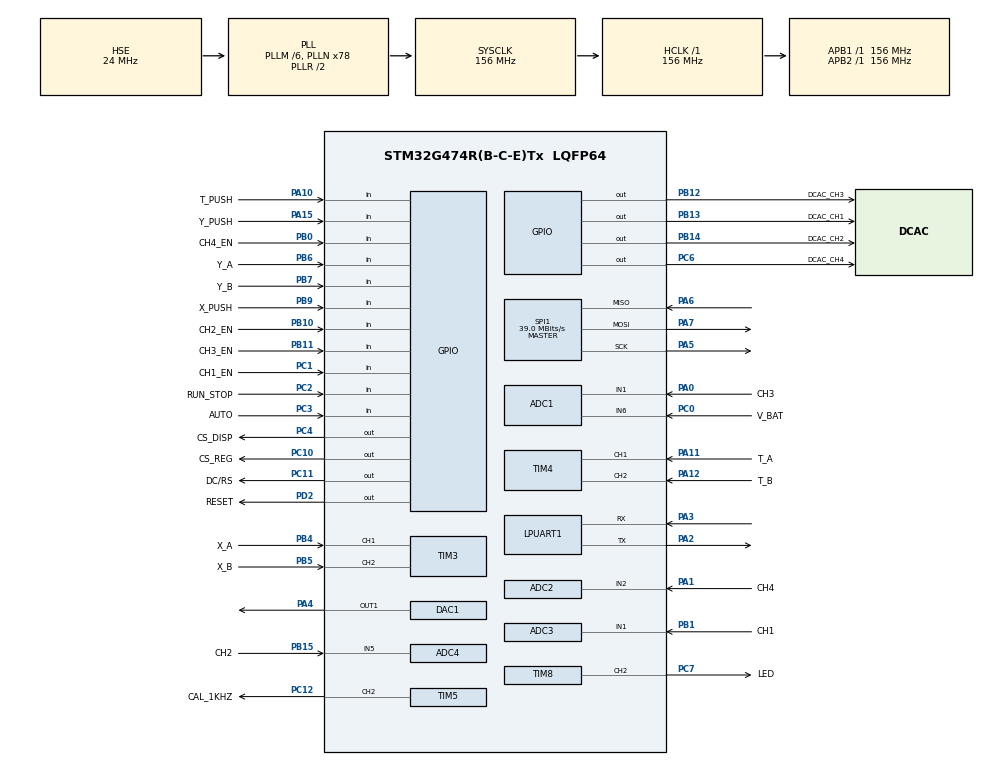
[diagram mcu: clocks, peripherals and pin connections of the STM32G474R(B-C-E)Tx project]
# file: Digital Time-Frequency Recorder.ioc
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ADC1.Channel-0\#ChannelRegularConversion=ADC_CHANNEL_1
ADC1.ClockPrescaler=ADC_CLOCK_ASYNC_DIV1
ADC1.DMAAccessModeView=ENABLE
ADC1.DMAContinuousRequests=ENABLE
ADC1.ExternalTrigConv=ADC_EXTERNALTRIG_T6_TRGO
ADC1.Mode=ADC_DUALMODE_REGSIMULT
ADC1.NbrOfConversion=1
ADC1.NbrOfConversionFlag=1
ADC1.OffsetNumber-0\#ChannelRegularConversion=ADC_OFFSET_NONE
ADC1.Overrun=ADC_OVR_DATA_OVERWRITTEN
ADC1.Rank-0\#ChannelRegularConversion=1
ADC1.SamplingTime-0\#ChannelRegularConversion=ADC_SAMPLETIME_2CYCLES_5
ADC1.master=1
ADC2.Channel-1\#ChannelRegularConversion=ADC_CHANNEL_2
ADC2.ClockPrescaler=ADC_CLOCK_ASYNC_DIV1
ADC2.DMAAccessModeView=ENABLE
ADC2.Mode=ADC_DUALMODE_REGSIMULT
ADC2.NbrOfConversionFlag=1
ADC2.OffsetNumber-1\#ChannelRegularConversion=ADC_OFFSET_NONE
ADC2.Rank-1\#ChannelRegularConversion=1
ADC2.SamplingTime-1\#ChannelRegularConversion=ADC_SAMPLETIME_2CYCLES_5
ADC3.Channel-3\#ChannelRegularConversion=ADC_CHANNEL_1
ADC3.ClockPrescaler=ADC_CLOCK_ASYNC_DIV1
ADC3.DMAAccessModeView=ENABLE
ADC3.DMAContinuousRequests=ENABLE
ADC3.ExternalTrigConv=ADC_EXTERNALTRIG_T6_TRGO
ADC3.Mode=ADC_DUALMODE_REGSIMULT
ADC3.NbrOfConversion=1
ADC3.NbrOfConversionFlag=1
ADC3.OffsetNumber-3\#ChannelRegularConversion=ADC_OFFSET_NONE
ADC3.Overrun=ADC_OVR_DATA_OVERWRITTEN
ADC3.Rank-3\#ChannelRegularConversion=1
ADC3.SamplingTime-3\#ChannelRegularConversion=ADC_SAMPLETIME_2CYCLES_5
ADC3.master=1
ADC4.Channel-1\#ChannelRegularConversion=ADC_CHANNEL_5
ADC4.ClockPrescaler=ADC_CLOCK_ASYNC_DIV1
ADC4.DMAAccessModeView=ENABLE
ADC4.Mode=ADC_DUALMODE_REGSIMULT
ADC4.NbrOfConversionFlag=1
ADC4.OffsetNumber-1\#ChannelRegularConversion=ADC_OFFSET_NONE
ADC4.Rank-1\#ChannelRegularConversion=1
ADC4.SamplingTime-1\#ChannelRegularConversion=ADC_SAMPLETIME_2CYCLES_5
DAC1.DAC_Trigger_OUT1-DAC_OUT1=DAC_TRIGGER_T2_TRGO
Dma.ADC1.2.Direction=DMA_PERIPH_TO_MEMORY
Dma.ADC1.2.EventEnable=DISABLE
Dma.ADC1.2.Instance=DMA1_Channel3
Dma.ADC1.2.MemDataAlignment=DMA_MDATAALIGN_WORD
Dma.ADC1.2.MemInc=DMA_MINC_ENABLE
Dma.ADC1.2.Mode=DMA_NORMAL
Dma.ADC1.2.PeriphDataAlignment=DMA_PDATAALIGN_WORD
Dma.ADC1.2.PeriphInc=DMA_PINC_DISABLE
Dma.ADC1.2.Polarity=HAL_DMAMUX_REQ_GEN_RISING
Dma.ADC1.2.Priority=DMA_PRIORITY_VERY_HIGH
Dma.ADC1.2.RequestNumber=1
Dma.ADC1.2.SignalID=NONE
Dma.ADC1.2.SyncEnable=DISABLE
Dma.ADC1.2.SyncPolarity=HAL_DMAMUX_SYNC_NO_EVENT
Dma.ADC1.2.SyncRequestNumber=1
Dma.ADC1.2.SyncSignalID=NONE
Dma.ADC3.3.Direction=DMA_PERIPH_TO_MEMORY
Dma.ADC3.3.EventEnable=DISABLE
Dma.ADC3.3.Instance=DMA1_Channel4
Dma.ADC3.3.MemDataAlignment=DMA_MDATAALIGN_WORD
Dma.ADC3.3.MemInc=DMA_MINC_ENABLE
Dma.ADC3.3.Mode=DMA_NORMAL
Dma.ADC3.3.PeriphDataAlignment=DMA_PDATAALIGN_WORD
Dma.ADC3.3.PeriphInc=DMA_PINC_DISABLE
Dma.ADC3.3.Polarity=HAL_DMAMUX_REQ_GEN_RISING
Dma.ADC3.3.Priority=DMA_PRIORITY_VERY_HIGH
Dma.ADC3.3.RequestNumber=1
Dma.ADC3.3.SignalID=NONE
Dma.ADC3.3.SyncEnable=DISABLE
Dma.ADC3.3.SyncPolarity=HAL_DMAMUX_SYNC_NO_EVENT
Dma.ADC3.3.SyncRequestNumber=1
Dma.ADC3.3.SyncSignalID=NONE
Dma.DAC1_CH1.1.Direction=DMA_MEMORY_TO_PERIPH
Dma.DAC1_CH1.1.EventEnable=DISABLE
Dma.DAC1_CH1.1.Instance=DMA1_Channel2
Dma.DAC1_CH1.1.MemDataAlignment=DMA_MDATAALIGN_HALFWORD
Dma.DAC1_CH1.1.MemInc=DMA_MINC_ENABLE
Dma.DAC1_CH1.1.Mode=DMA_CIRCULAR
Dma.DAC1_CH1.1.PeriphDataAlignment=DMA_PDATAALIGN_WORD
Dma.DAC1_CH1.1.PeriphInc=DMA_PINC_DISABLE
Dma.DAC1_CH1.1.Polarity=HAL_DMAMUX_REQ_GEN_RISING
Dma.DAC1_CH1.1.Priority=DMA_PRIORITY_LOW
Dma.DAC1_CH1.1.RequestNumber=1
Dma.DAC1_CH1.1.SignalID=NONE
Dma.DAC1_CH1.1.SyncEnable=DISABLE
Dma.DAC1_CH1.1.SyncPolarity=HAL_DMAMUX_SYNC_NO_EVENT
Dma.DAC1_CH1.1.SyncRequestNumber=1
Dma.DAC1_CH1.1.SyncSignalID=NONE
Dma.Request0=SPI1_TX
Dma.Request1=DAC1_CH1
Dma.Request2=ADC1
Dma.Request3=ADC3
Dma.SPI1_TX.0.Direction=DMA_MEMORY_TO_PERIPH
Dma.SPI1_TX.0.EventEnable=DISABLE
Dma.SPI1_TX.0.Instance=DMA1_Channel1
Dma.SPI1_TX.0.MemDataAlignment=DMA_MDATAALIGN_BYTE
Dma.SPI1_TX.0.MemInc=DMA_MINC_ENABLE
Dma.SPI1_TX.0.Mode=DMA_NORMAL
Dma.SPI1_TX.0.PeriphDataAlignment=DMA_PDATAALIGN_BYTE
Dma.SPI1_TX.0.PeriphInc=DMA_PINC_DISABLE
Dma.SPI1_TX.0.Polarity=HAL_DMAMUX_REQ_GEN_RISING
Dma.SPI1_TX.0.Priority=DMA_PRIORITY_HIGH
Dma.SPI1_TX.0.RequestNumber=1
Dma.SPI1_TX.0.SignalID=NONE
Dma.SPI1_TX.0.SyncEnable=DISABLE
Dma.SPI1_TX.0.SyncPolarity=HAL_DMAMUX_SYNC_NO_EVENT
Dma.SPI1_TX.0.SyncRequestNumber=1
Dma.SPI1_TX.0.SyncSignalID=NONE
Mcu.Family=STM32G4
Mcu.Name=STM32G474R(B-C-E)Tx
Mcu.Package=LQFP64
NVIC.DMA1_Channel1_IRQn=true\:0\:0\:false\:false\:true\:false\:true\:true
NVIC.DMA1_Channel2_IRQn=true\:0\:0\:false\:false\:true\:false\:true\:true
NVIC.DMA1_Channel3_IRQn=true\:0\:0\:false\:false\:true\:false\:true\:true
NVIC.DMA1_Channel4_IRQn=true\:0\:0\:false\:false\:true\:false\:true\:true
NVIC.PriorityGroup=NVIC_PRIORITYGROUP_4
NVIC.TIM7_DAC_IRQn=true\:0\:0\:false\:false\:true\:true\:true\:true
PA0.GPIO_Label=CH3
PA0.Mode=IN1-Single-Ended
PA0.Signal=ADC1_IN1
PA1.GPIO_Label=CH4
PA1.Mode=IN2-Single-Ended
PA1.Signal=ADC2_IN2
PA10.GPIO_Label=T_PUSH
PA10.Signal=GPIO_Input
PA11.GPIO_Label=T_A
PA11.Signal=S_TIM4_CH1
PA12.GPIO_Label=T_B
PA12.Signal=S_TIM4_CH2
PA13.GPIO_Label=T_SWDIO
PA13.Mode=Serial_Wire
PA13.Signal=SYS_JTMS-SWDIO
PA14.GPIO_Label=T_SWCLK
PA14.Mode=Serial_Wire
PA14.Signal=SYS_JTCK-SWCLK
PA15.GPIO_Label=Y_PUSH
PA15.Signal=GPIO_Input
PA2.Mode=Asynchronous
PA2.Signal=LPUART1_TX
PA3.Mode=Asynchronous
PA3.Signal=LPUART1_RX
PA4.Signal=COMP_DAC11_group
PA5.GPIO_Speed=GPIO_SPEED_FREQ_VERY_HIGH
PA5.Mode=Full_Duplex_Master
PA5.Signal=SPI1_SCK
PA6.GPIO_Speed=GPIO_SPEED_FREQ_VERY_HIGH
PA6.Mode=Full_Duplex_Master
PA6.Signal=SPI1_MISO
PA7.GPIO_Speed=GPIO_SPEED_FREQ_VERY_HIGH
PA7.Mode=Full_Duplex_Master
PA7.Signal=SPI1_MOSI
PB0.GPIO_Label=CH4_EN
PB0.Signal=GPIO_Input
PB1.GPIO_Label=CH1
PB1.Mode=IN1-Single-Ended
PB1.Signal=ADC3_IN1
PB10.GPIO_Label=CH2_EN
PB10.Signal=GPIO_Input
PB11.GPIO_Label=CH3_EN
PB11.Signal=GPIO_Input
PB12.GPIO_Label=DCAC_CH3
PB12.Signal=GPIO_Output
PB13.GPIO_Label=DCAC_CH1
PB13.Signal=GPIO_Output
PB14.GPIO_Label=DCAC_CH2
PB14.Signal=GPIO_Output
PB15.GPIO_Label=CH2
PB15.Mode=IN5-Single-Ended
PB15.Signal=ADC4_IN5
PB3.GPIO_Label=T_SWO
PB3.Signal=SYS_JTDO-SWO
PB4.GPIO_Label=X_A
PB4.Signal=S_TIM3_CH1
PB5.GPIO_Label=X_B
PB5.Signal=S_TIM3_CH2
PB6.GPIO_Label=Y_A
PB6.Signal=GPIO_Input
PB7.GPIO_Label=Y_B
PB7.Signal=GPIO_Input
PB9.GPIO_Label=X_PUSH
PB9.Signal=GPIO_Input
PC0.GPIO_Label=V_BAT
PC0.Mode=IN6-Single-Ended
PC0.Signal=ADC1_IN6
PC1.GPIO_Label=CH1_EN
PC1.Signal=GPIO_Input
PC10.GPIO_Label=CS_REG
PC10.PinState=GPIO_PIN_SET
PC10.Signal=GPIO_Output
PC11.GPIO_Label=DC/RS
PC11.Signal=GPIO_Output
PC12.GPIO_Label=CAL_1KHZ
PC12.Signal=S_TIM5_CH2
PC14-OSC32_IN.GPIO_Label=RCC_OSC32_IN
PC14-OSC32_IN.Signal=RCC_OSC32_IN
PC15-OSC32_OUT.GPIO_Label=RCC_OSC32_OUT
PC15-OSC32_OUT.Signal=RCC_OSC32_OUT
PC2.GPIO_Label=RUN_STOP
PC2.Signal=GPIO_Input
PC3.GPIO_Label=AUTO
PC3.Signal=GPIO_Input
PC4.GPIO_Label=CS_DISP
PC4.PinState=GPIO_PIN_SET
PC4.Signal=GPIO_Output
PC6.GPIO_Label=DCAC_CH4
PC6.Signal=GPIO_Output
PC7.GPIO_Label=LED
PC7.Signal=S_TIM8_CH2
PD2.GPIO_Label=RESET
PD2.PinState=GPIO_PIN_SET
PD2.Signal=GPIO_Output
PF0-OSC_IN.GPIO_Label=RCC_OSC_IN
PF0-OSC_IN.Mode=HSE-External-Oscillator
PF0-OSC_IN.Signal=RCC_OSC_IN
PF1-OSC_OUT.GPIO_Label=RCC_OSC_OUT
PF1-OSC_OUT.Mode=HSE-External-Oscillator
PF1-OSC_OUT.Signal=RCC_OSC_OUT
ProjectManager.HeapSize=0x1000
ProjectManager.StackSize=0x800
ProjectManager.TargetToolchain=STM32CubeIDE
RCC.ADC12CLockSelection=RCC_ADC12CLKSOURCE_PLL
RCC.ADC12Freq_Value=52000000
RCC.ADC345CLockSelection=RCC_ADC345CLKSOURCE_PLL
RCC.ADC345Freq_Value=52000000
RCC.AHBFreq_Value=156000000
RCC.APB1Freq_Value=156000000
RCC.APB1TimFreq_Value=156000000
RCC.APB2Freq_Value=156000000
RCC.APB2TimFreq_Value=156000000
RCC.CortexFreq_Value=156000000
RCC.EXTERNAL_CLOCK_VALUE=12288000
RCC.HCLKFreq_Value=156000000
RCC.HSE_VALUE=24000000
RCC.HSI48_VALUE=48000000
RCC.HSI_VALUE=16000000
RCC.LSE_VALUE=32768
RCC.PLLM=RCC_PLLM_DIV6
RCC.PLLN=78
RCC.PLLP=RCC_PLLP_DIV6
RCC.PLLSourceVirtual=RCC_PLLSOURCE_HSE
RCC.RTCClockSelection=RCC_RTCCLKSOURCE_LSE
RCC.SYSCLKFreq_VALUE=156000000
RCC.SYSCLKSource=RCC_SYSCLKSOURCE_PLLCLK
RCC.USBFreq_Value=156000000
RCC.VCOOutputFreq_Value=312000000
SH.COMP_DAC11_group.0=DAC1_OUT1,DAC_OUT1
SH.S_TIM3_CH1.0=TIM3_CH1,Encoder_Interface
SH.S_TIM3_CH2.0=TIM3_CH2,Encoder_Interface
SH.S_TIM4_CH1.0=TIM4_CH1,Encoder_Interface
SH.S_TIM4_CH2.0=TIM4_CH2,Encoder_Interface
SH.S_TIM5_CH2.0=TIM5_CH2,PWM Generation2 CH2
SH.S_TIM8_CH2.0=TIM8_CH2,PWM Generation2 CH2
SPI1.BaudRatePrescaler=SPI_BAUDRATEPRESCALER_4
SPI1.CalculateBaudRate=39.0 MBits/s
SPI1.DataSize=SPI_DATASIZE_8BIT
SPI1.Direction=SPI_DIRECTION_2LINES
SPI1.Mode=SPI_MODE_MASTER
SPI1.NSSPMode=SPI_NSS_PULSE_DISABLE
SPI1.VirtualType=VM_MASTER
TIM2.PeriodNoDither=311
TIM2.TIM_MasterOutputTrigger=TIM_TRGO_UPDATE
TIM3.EncoderMode=TIM_ENCODERMODE_TI12
TIM3.IC1Filter=10
TIM3.IC2Filter=10
TIM4.EncoderMode=TIM_ENCODERMODE_TI12
TIM4.IC1Filter=10
TIM4.IC2Filter=10
TIM5.Channel-PWM\ Generation2\ CH2=TIM_CHANNEL_2
TIM5.PeriodNoDither=999
TIM5.Prescaler=155
TIM5.PulseNoDither_2=500
TIM6.PeriodNoDither=44
TIM6.TIM_MasterOutputTrigger=TIM_TRGO_UPDATE
TIM7.AutoReloadPreload=TIM_AUTORELOAD_PRELOAD_ENABLE
TIM7.PeriodNoDither=999
TIM7.Prescaler=155
TIM7.TIM_MasterOutputTrigger=TIM_TRGO_UPDATE
TIM8.Channel-PWM\ Generation2\ CH2=TIM_CHANNEL_2
TIM8.PeriodNoDither=7799
TIM8.PulseNoDither_2=7799
VP_SYS_VS_DBSignals.Mode=DisableDeadBatterySignals
VP_TIM2_VS_ClockSourceINT.Mode=Internal
VP_TIM6_VS_ClockSourceINT.Mode=Enable_Timer
VP_TIM7_VS_ClockSourceINT.Mode=Enable_Timer
board=NUCLEO-G474RE

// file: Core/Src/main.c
/* USER CODE BEGIN Header */
/**
  ******************************************************************************
  * @file           : main.c
  * @brief          : Main program body
  ******************************************************************************
  * @attention
  *
  * Copyright (c) 2026 STMicroelectronics.
  * All rights reserved.
  *
  * This software is licensed under terms that can be found in the LICENSE file
  * in the root directory of this software component.
  * If no LICENSE file comes with this software, it is provided AS-IS.
  *
  ******************************************************************************
  */
/* USER CODE END Header */
#include "main.h"
#include "adc.h"
#include "dac.h"
#include "dma.h"
#include "usart.h"
#include "spi.h"
#include "tim.h"
#include "gpio.h"

/* USER CODE BEGIN Includes */
#include <stdio.h>
#include "app.h"
/* USER CODE END Includes */

void SystemClock_Config(void);

/* USER CODE BEGIN 0 */
/* printf -> LPUART1 (wirtualny COM ST-LINK) */
int __io_putchar(int ch)
{
  uint8_t c = (uint8_t)ch;
  HAL_UART_Transmit(&hlpuart1, &c, 1, 10);
  return ch;
}

/* USER CODE END 0 */

int main(void)
{

  /* MCU Configuration--------------------------------------------------------*/

  /* Reset of all peripherals, Initializes the Flash interface and the Systick. */
  HAL_Init();

  /* Configure the system clock */
  SystemClock_Config();

  /* Initialize all configured peripherals */
  MX_GPIO_Init();
  MX_DMA_Init();
  MX_ADC1_Init();
  MX_ADC2_Init();
  MX_ADC3_Init();
  MX_ADC4_Init();
  MX_LPUART1_UART_Init();
  MX_SPI1_Init();
  MX_TIM3_Init();
  MX_TIM4_Init();
  MX_TIM5_Init();
  MX_TIM7_Init();
  MX_TIM8_Init();
  MX_TIM6_Init();
  MX_DAC1_Init();
  MX_TIM2_Init();
  /* USER CODE BEGIN 2 */
  app_init();
  /* USER CODE END 2 */

  /* Infinite loop */
  while (1)
  {

    /* USER CODE BEGIN 3 */
    app_poll();
  }
  /* USER CODE END 3 */
}

void SystemClock_Config(void)
{
  RCC_OscInitTypeDef RCC_OscInitStruct = {0};
  RCC_ClkInitTypeDef RCC_ClkInitStruct = {0};

  /** Configure the main internal regulator output voltage
  */
  HAL_PWREx_ControlVoltageScaling(PWR_REGULATOR_VOLTAGE_SCALE1_BOOST);

  /** Initializes the RCC Oscillators according to the specified parameters
  * in the RCC_OscInitTypeDef structure.
  */
  RCC_OscInitStruct.OscillatorType = RCC_OSCILLATORTYPE_HSE;
  RCC_OscInitStruct.HSEState = RCC_HSE_ON;
  RCC_OscInitStruct.PLL.PLLState = RCC_PLL_ON;
  RCC_OscInitStruct.PLL.PLLSource = RCC_PLLSOURCE_HSE;
  RCC_OscInitStruct.PLL.PLLM = RCC_PLLM_DIV6;
  RCC_OscInitStruct.PLL.PLLN = 78;
  RCC_OscInitStruct.PLL.PLLP = RCC_PLLP_DIV6;
  RCC_OscInitStruct.PLL.PLLQ = RCC_PLLQ_DIV2;
  RCC_OscInitStruct.PLL.PLLR = RCC_PLLR_DIV2;
  if (HAL_RCC_OscConfig(&RCC_OscInitStruct) != HAL_OK)
  {
    Error_Handler();
  }

  /** Initializes the CPU, AHB and APB buses clocks
  */
  RCC_ClkInitStruct.ClockType = RCC_CLOCKTYPE_HCLK|RCC_CLOCKTYPE_SYSCLK
                              |RCC_CLOCKTYPE_PCLK1|RCC_CLOCKTYPE_PCLK2;
  RCC_ClkInitStruct.SYSCLKSource = RCC_SYSCLKSOURCE_PLLCLK;
  RCC_ClkInitStruct.AHBCLKDivider = RCC_SYSCLK_DIV1;
  RCC_ClkInitStruct.APB1CLKDivider = RCC_HCLK_DIV1;
  RCC_ClkInitStruct.APB2CLKDivider = RCC_HCLK_DIV1;

  if (HAL_RCC_ClockConfig(&RCC_ClkInitStruct, FLASH_LATENCY_4) != HAL_OK)
  {
    Error_Handler();
  }
}

void Error_Handler(void)
{
  __disable_irq();
  while (1)
  {
  }
}
